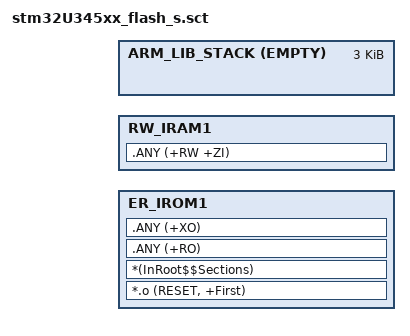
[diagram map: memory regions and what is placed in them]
#! armclang --target=arm-arm-none-eabi -march=armv8-m.main -E -xc
/*************************************************************************************************/
#include "appli_region_defs.h"
/*************************************************************************************************/
#define __STACK_SIZE           0x0000C00
#define __HEAP_SIZE            0x0000000

#define __STACK_TOP            (SRAM2_BASE_S + SRAM2_SIZE)    /* starts at end of RAM */
#define __HEAP_BASE            (AlignExpr(+0, 8))              /* starts after RW_RAM section, 8 byte aligned */

#define __RO_BASE              S_CODE_START
#define __RO_SIZE              S_CODE_SIZE

#define __RW_BASE              S_RAM_START
#define __RW_SIZE              (S_RAM_SIZE - __STACK_SIZE - __HEAP_SIZE)

/*************************************************************************************************/
LR_IROM1 __RO_BASE  __RO_SIZE  {                    ; load region size_region
  ER_IROM1 __RO_BASE  __RO_SIZE  {                  ; load address = execution address
   *.o (RESET, +First)
   *(InRoot$$Sections)
   .ANY (+RO)
   .ANY (+XO)
  }

  RW_IRAM1 __RW_BASE __RW_SIZE {                    ; RW data
   .ANY (+RW +ZI)
  }

#if __HEAP_SIZE > 0
  ARM_LIB_HEAP __HEAP_BASE EMPTY __HEAP_SIZE {      ; Reserve empty region for heap
  }
#endif

  ARM_LIB_STACK __STACK_TOP EMPTY -__STACK_SIZE {   ; Reserve empty region for stack
  }
}
